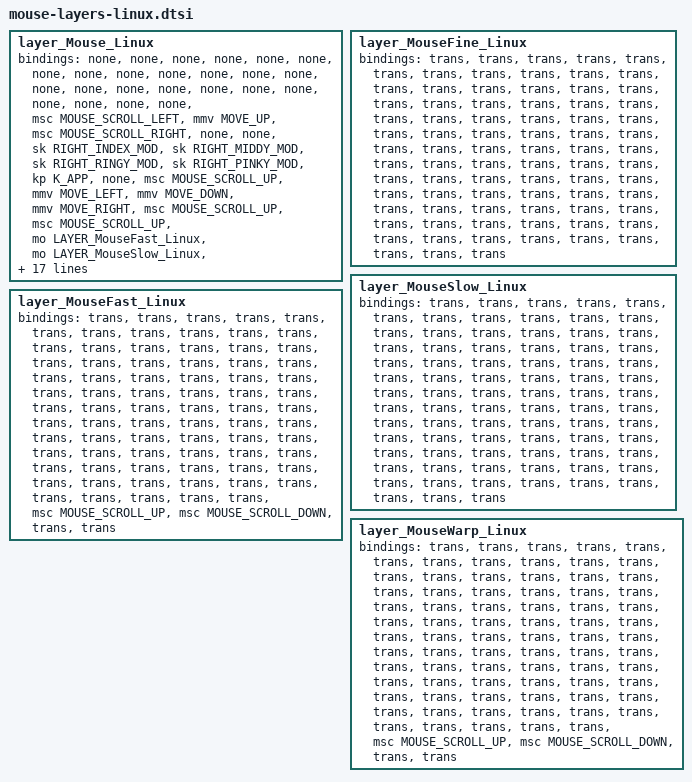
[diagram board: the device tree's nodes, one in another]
/*
 * Linux Mouse Layers
 *
 * This file contains Linux-specific versions of mouse-related layers.
 */

        layer_Mouse_Linux {
            bindings = <
  &none                   &none                   &none                &none                    &none                                                                                                                                             &none                &none                    &none                &none      &none
  &none                   &none                   &none                &none                    &none                   &none                                                                                             &none                   &none                &none                    &none                &none      &none
  &none                   &none  &msc MOUSE_SCROLL_LEFT         &mmv MOVE_UP  &msc MOUSE_SCROLL_RIGHT                   &none                                                                                             &none     &sk RIGHT_INDEX_MOD  &sk RIGHT_MIDDY_MOD      &sk RIGHT_RINGY_MOD  &sk RIGHT_PINKY_MOD  &kp K_APP
  &none    &msc MOUSE_SCROLL_UP          &mmv MOVE_LEFT       &mmv MOVE_DOWN          &mmv MOVE_RIGHT    &msc MOUSE_SCROLL_UP                                                                              &msc MOUSE_SCROLL_UP  &mo LAYER_MouseFast_Linux  &mo LAYER_MouseSlow_Linux  &mo LAYER_MouseFine_Linux  &mo LAYER_MouseWarp_Linux   &mkp MB4
  &none  &msc MOUSE_SCROLL_DOWN          &kp _LINUX_CUT      &kp _LINUX_COPY         &kp _LINUX_PASTE  &msc MOUSE_SCROLL_DOWN  &mkp MCLK  &kp K_APP  &mkp MB5  &kp _LINUX_PASTE  &kp _LINUX_COPY  &kp _LINUX_PASTE  &msc MOUSE_SCROLL_DOWN  &msc MOUSE_SCROLL_LEFT         &mmv MOVE_UP  &msc MOUSE_SCROLL_RIGHT            &mkp LCLK   &mkp MB5
  &none  &mo LAYER_MouseWarp_Linux  &mo LAYER_MouseFine_Linux  &mo LAYER_MouseSlow_Linux   &mo LAYER_MouseFast_Linux                          &mkp LCLK  &mkp RCLK  &mkp MB4       &none  &tog LAYER_Mouse_Linux       &none                                  &mmv MOVE_LEFT       &mmv MOVE_DOWN          &mmv MOVE_RIGHT            &mkp RCLK  &mkp MCLK
            >;
        };

        layer_MouseFine_Linux {
            bindings = <
 &trans  &trans  &trans  &trans  &trans                                                                  &trans  &trans  &trans  &trans  &trans
 &trans  &trans  &trans  &trans  &trans  &trans                                                  &trans  &trans  &trans  &trans  &trans  &trans
 &trans  &trans  &trans  &trans  &trans  &trans                                                  &trans  &trans  &trans  &trans  &trans  &trans
 &trans  &trans  &trans  &trans  &trans  &trans                                                  &trans  &trans  &trans  &trans  &trans  &trans
 &trans  &trans  &trans  &trans  &trans  &trans  &trans  &trans  &trans  &trans  &trans  &trans  &trans  &trans  &trans  &trans  &trans  &trans
 &trans  &trans  &trans  &trans  &trans          &trans  &trans  &trans  &trans  &trans  &trans          &trans  &trans  &trans  &trans  &trans
            >;
        };

        layer_MouseSlow_Linux {
            bindings = <
 &trans  &trans  &trans  &trans  &trans                                                                  &trans  &trans  &trans  &trans  &trans
 &trans  &trans  &trans  &trans  &trans  &trans                                                  &trans  &trans  &trans  &trans  &trans  &trans
 &trans  &trans  &trans  &trans  &trans  &trans                                                  &trans  &trans  &trans  &trans  &trans  &trans
 &trans  &trans  &trans  &trans  &trans  &trans                                                  &trans  &trans  &trans  &trans  &trans  &trans
 &trans  &trans  &trans  &trans  &trans  &trans  &trans  &trans  &trans  &trans  &trans  &trans  &trans  &trans  &trans  &trans  &trans  &trans
 &trans  &trans  &trans  &trans  &trans          &trans  &trans  &trans  &trans  &trans  &trans          &trans  &trans  &trans  &trans  &trans
            >;
        };

        layer_MouseFast_Linux {
            bindings = <
 &trans  &trans  &trans  &trans  &trans                                                                  &trans  &trans  &trans  &trans  &trans
 &trans  &trans  &trans  &trans  &trans  &trans                                                  &trans  &trans  &trans  &trans  &trans  &trans
 &trans  &trans  &trans  &trans  &trans  &trans                                                  &trans  &trans  &trans  &trans  &trans  &trans
 &trans  &trans  &trans  &trans  &trans  &trans                                                  &trans  &trans  &trans  &trans  &trans  &trans
 &trans  &trans  &trans  &trans  &trans  &trans  &trans  &trans  &trans  &trans  &trans  &trans  &trans  &trans  &trans  &trans  &trans  &trans
 &trans  &trans  &trans  &trans  &trans          &trans  &trans  &trans  &trans  &trans  &trans          &trans  &msc MOUSE_SCROLL_UP  &msc MOUSE_SCROLL_DOWN  &trans  &trans
            >;
        };

        layer_MouseWarp_Linux {
            bindings = <
 &trans  &trans  &trans  &trans  &trans                                                                  &trans  &trans  &trans  &trans  &trans
 &trans  &trans  &trans  &trans  &trans  &trans                                                  &trans  &trans  &trans  &trans  &trans  &trans
 &trans  &trans  &trans  &trans  &trans  &trans                                                  &trans  &trans  &trans  &trans  &trans  &trans
 &trans  &trans  &trans  &trans  &trans  &trans                                                  &trans  &trans  &trans  &trans  &trans  &trans
 &trans  &trans  &trans  &trans  &trans  &trans  &trans  &trans  &trans  &trans  &trans  &trans  &trans  &trans  &trans  &trans  &trans  &trans
 &trans  &trans  &trans  &trans  &trans          &trans  &trans  &trans  &trans  &trans  &trans          &trans  &msc MOUSE_SCROLL_UP  &msc MOUSE_SCROLL_DOWN  &trans  &trans
            >;
        };
